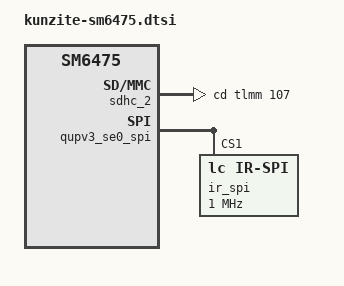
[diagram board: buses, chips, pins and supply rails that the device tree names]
/* And public attribution of longcheer platforms */
#include "longcheer-sm6475-common.dtsi"
#include "kunzite-pinctrl.dtsi"

&sdhc_2 {
	cd-gpios = <&tlmm 107 GPIO_ACTIVE_HIGH>;
};

&soc {
	qcom,rmtfs_sharedmem@0 {
		compatible = "qcom,sharedmem-uio";
		reg = <0x0 0x800000>;
		reg-names = "rmtfs";
		qcom,client-id = <0x00000001>;
	};
};

/* IR Bringup */
&qupv3_se0_spi {
	status = "ok";
	/* Add slave device config here */
	ir_spi@1 {
		compatible = "lc,ir-spi";
		#address-cells = <1>;
		#size-cells = <1>;
		reg = <1>; /* Chip select 0 */
		spi-max-frequency = <1000000>;
		spi-cpol;
		status = "ok";
	};
};
